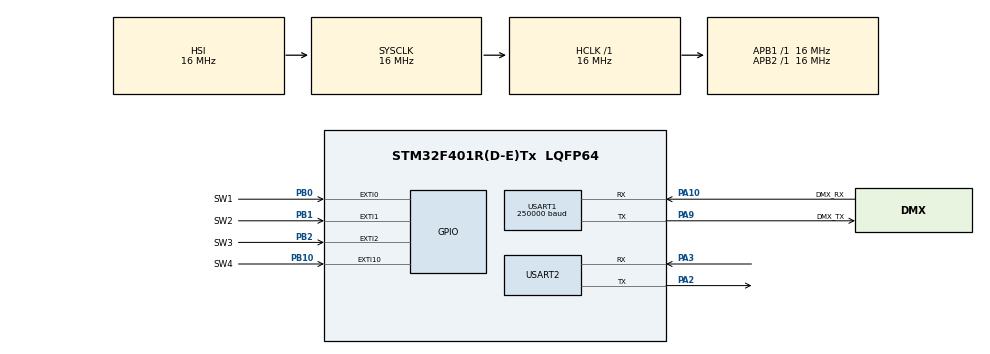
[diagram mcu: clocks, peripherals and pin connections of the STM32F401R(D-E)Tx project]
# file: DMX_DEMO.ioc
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Mcu.Family=STM32F4
Mcu.Name=STM32F401R(D-E)Tx
Mcu.Package=LQFP64
NVIC.EXTI0_IRQn=true\:0\:0\:false\:false\:true\:true\:true\:true
NVIC.EXTI15_10_IRQn=true\:0\:0\:false\:false\:true\:true\:true\:true
NVIC.EXTI1_IRQn=true\:0\:0\:false\:false\:true\:true\:true\:true
NVIC.EXTI2_IRQn=true\:0\:0\:false\:false\:true\:true\:true\:true
NVIC.PriorityGroup=NVIC_PRIORITYGROUP_4
NVIC.USART2_IRQn=true\:0\:0\:false\:false\:true\:true\:true\:true
PA10.GPIO_Label=DMX_RX
PA10.Mode=Asynchronous
PA10.Signal=USART1_RX
PA13.Mode=Serial_Wire
PA13.Signal=SYS_JTMS-SWDIO
PA14.Mode=Serial_Wire
PA14.Signal=SYS_JTCK-SWCLK
PA2.Mode=Asynchronous
PA2.Signal=USART2_TX
PA3.Mode=Asynchronous
PA3.Signal=USART2_RX
PA9.GPIO_Label=DMX_TX
PA9.Mode=Asynchronous
PA9.Signal=USART1_TX
PB0.GPIO_Label=SW1
PB0.Signal=GPXTI0
PB1.GPIO_Label=SW2
PB1.Signal=GPXTI1
PB10.GPIO_Label=SW4
PB10.Signal=GPXTI10
PB2.GPIO_Label=SW3
PB2.Signal=GPXTI2
ProjectManager.HeapSize=0x200
ProjectManager.StackSize=0x400
ProjectManager.TargetToolchain=STM32CubeIDE
RCC.AHBFreq_Value=16000000
RCC.APB1Freq_Value=16000000
RCC.APB2Freq_Value=16000000
RCC.CortexFreq_Value=16000000
RCC.HSE_VALUE=25000000
RCC.HSI_VALUE=16000000
RCC.LSE_VALUE=32768
RCC.SYSCLKFreq_VALUE=16000000
RCC.VCOOutputFreq_Value=192000000
USART1.BaudRate=250000
USART1.VirtualMode=VM_ASYNC
USART1.WordLength=WORDLENGTH_9B
USART2.VirtualMode=VM_ASYNC
board=custom

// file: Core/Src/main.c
/* USER CODE BEGIN Header */
/**
  ******************************************************************************
  * @file           : main.c
  * @brief          : Main program body
  ******************************************************************************
  * @attention
  *
  * Copyright (c) 2023 STMicroelectronics.
  * All rights reserved.
  *
  * This software is licensed under terms that can be found in the LICENSE file
  * in the root directory of this software component.
  * If no LICENSE file comes with this software, it is provided AS-IS.
  *
  ******************************************************************************
  */
/* USER CODE END Header */
#include "main.h"
#include "uart.h"
#include "DMX512.h"
#include "stdio.h"

static unsigned char dmxDataDemo[513] = {255};

void SystemClock_Config(void);
static void MX_GPIO_Init(void);

int main(void)
{

  /* MCU Configuration--------------------------------------------------------*/

  /* Reset of all peripherals, Initializes the Flash interface and the Systick. */
  HAL_Init();

  /* Configure the system clock */
  SystemClock_Config();

  /* Initialize all configured peripherals */
  MX_GPIO_Init();
  MX_USART1_UART_Init();
  MX_USART2_UART_Init();
//  clrDmxData(dmxDataDemo);
  /* Infinite loop */
  /* USER CODE BEGIN WHILE */
//  int i;
//  for(i=0;i<513;i++){
//	  if(i%4 == 0){
//		 dmxDataDemo[i] = ;
//
//	  }
//  }

//  DMX_Write_Add(1);
  while (1)
  {
    /* USER CODE END WHILE */
	  DMX_Send_Packet(512, dmxDataDemo);
	  HAL_GPIO_TogglePin(LED1_Port, LED1_Pin);
	  HAL_Delay(500);
  }
}

void SystemClock_Config(void)
{
  RCC_OscInitTypeDef RCC_OscInitStruct = {0};
  RCC_ClkInitTypeDef RCC_ClkInitStruct = {0};

  /** Configure the main internal regulator output voltage
  */
  __HAL_RCC_PWR_CLK_ENABLE();
  __HAL_PWR_VOLTAGESCALING_CONFIG(PWR_REGULATOR_VOLTAGE_SCALE2);

  /** Initializes the RCC Oscillators according to the specified parameters
  * in the RCC_OscInitTypeDef structure.
  */
  RCC_OscInitStruct.OscillatorType = RCC_OSCILLATORTYPE_HSI;
  RCC_OscInitStruct.HSIState = RCC_HSI_ON;
  RCC_OscInitStruct.HSICalibrationValue = RCC_HSICALIBRATION_DEFAULT;
  RCC_OscInitStruct.PLL.PLLState = RCC_PLL_NONE;
  if (HAL_RCC_OscConfig(&RCC_OscInitStruct) != HAL_OK)
  {
    Error_Handler();
  }

  /** Initializes the CPU, AHB and APB buses clocks
  */
  RCC_ClkInitStruct.ClockType = RCC_CLOCKTYPE_HCLK|RCC_CLOCKTYPE_SYSCLK
                              |RCC_CLOCKTYPE_PCLK1|RCC_CLOCKTYPE_PCLK2;
  RCC_ClkInitStruct.SYSCLKSource = RCC_SYSCLKSOURCE_HSI;
  RCC_ClkInitStruct.AHBCLKDivider = RCC_SYSCLK_DIV1;
  RCC_ClkInitStruct.APB1CLKDivider = RCC_HCLK_DIV1;
  RCC_ClkInitStruct.APB2CLKDivider = RCC_HCLK_DIV1;

  if (HAL_RCC_ClockConfig(&RCC_ClkInitStruct, FLASH_LATENCY_0) != HAL_OK)
  {
    Error_Handler();
  }
}

static void MX_GPIO_Init(void)
{
  GPIO_InitTypeDef GPIO_InitStruct = {0};

  /* GPIO Ports Clock Enable */
  __HAL_RCC_GPIOA_CLK_ENABLE();
  __HAL_RCC_GPIOB_CLK_ENABLE();

  GPIO_InitStruct.Pin = LED1_Pin;
  GPIO_InitStruct.Mode = GPIO_MODE_OUTPUT_PP;
  GPIO_InitStruct.Pull = GPIO_NOPULL;
  GPIO_InitStruct.Speed = GPIO_SPEED_FREQ_LOW;
  HAL_GPIO_Init(GPIOA, &GPIO_InitStruct);

  /*Configure GPIO pins : SW1_Pin SW2_Pin SW3_Pin SW4_Pin */
  GPIO_InitStruct.Pin = SW1_Pin|SW2_Pin|SW3_Pin|SW4_Pin;
  GPIO_InitStruct.Mode = GPIO_MODE_IT_RISING;
  GPIO_InitStruct.Pull = GPIO_NOPULL;
  HAL_GPIO_Init(GPIOB, &GPIO_InitStruct);

  /* EXTI interrupt init*/
  HAL_NVIC_SetPriority(EXTI0_IRQn, 0, 0);
  HAL_NVIC_EnableIRQ(EXTI0_IRQn);

  HAL_NVIC_SetPriority(EXTI1_IRQn, 0, 0);
  HAL_NVIC_EnableIRQ(EXTI1_IRQn);

  HAL_NVIC_SetPriority(EXTI2_IRQn, 0, 0);
  HAL_NVIC_EnableIRQ(EXTI2_IRQn);

  HAL_NVIC_SetPriority(EXTI15_10_IRQn, 0, 0);
  HAL_NVIC_EnableIRQ(EXTI15_10_IRQn);

}

void Error_Handler(void)
{
  __disable_irq();
  while (1)
  {
  }
}
